# UPD70F3508 register map
Vendor: Renesas; Series: V850E2/Px4; File version: 1.0
CPU: other r0p0, little endian, no MPU, FPU, 4 interrupt priority bits
Registers are 8-bit, read-write, reset 0x0 unless marked. A register's access mark holds for its fields unless they carry their own. Offsets are from the block's base; [hi:lo] are bit positions.

## CSIG0_B0 — Clocked Serial Interface G 0 - base0 region (CTL1, CTL2, CFG0)
Base 0xFF700010
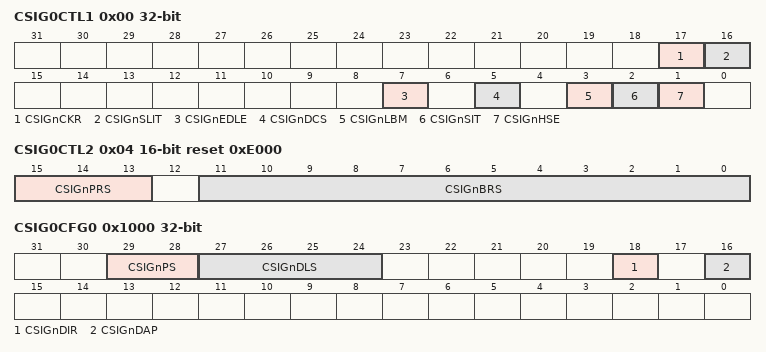
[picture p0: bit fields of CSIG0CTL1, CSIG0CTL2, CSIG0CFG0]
0x00 CSIG0CTL1 32-bit — CSIG0 Control Register 1
  [17] CSIGnCKR — Clock phase selection: 0=SCK default high, 1=SCK default low
  [16] CSIGnSLIT — TIC interrupt timing: 0=after transfer, 1=when TX0W/H free
  [7] CSIGnEDLE — Extended data length enable: 0=disabled, 1=enabled
  [5] CSIGnDCS — Data consistency check enable: 0=disabled, 1=enabled
  [3] CSIGnLBM — Loop-back mode: 0=deactivated, 1=activated
  [2] CSIGnSIT — Interrupt delay: 0=no delay, 1=half-clock delay
  [1] CSIGnHSE — Handshake enable: 0=disabled, 1=enabled
0x04 CSIG0CTL2 16-bit reset 0xE000 — CSIG0 Control Register 2 - baud rate generator
  [15:13] CSIGnPRS — Prescaler select [2:0]: 000-110=PCLK/2^m master, 111=slave ext clock
  [11:0] CSIGnBRS — Baud rate select [11:0]: 0=BRG stopped, 1-4095=divisor k
0x1000 CSIG0CFG0 32-bit — CSIG0 Configuration Register 0 - protocol, data length, parity, direction, clock/data phase
  [29:28] CSIGnPS — Parity select [1:0]: 00=none, 01=fixed-0, 10=odd, 11=even
  [27:24] CSIGnDLS — Data length select [3:0]: 0=16-bit, 1-15=N bits
  [18] CSIGnDIR — Transfer direction: 0=MSB first, 1=LSB first
  [16] CSIGnDAP — Data phase selection (used with CKR for SPI mode)

## CSIG1_B0 — Clocked Serial Interface G 1 - base0 region (CTL1, CTL2, CFG0)
Base 0xFF710010
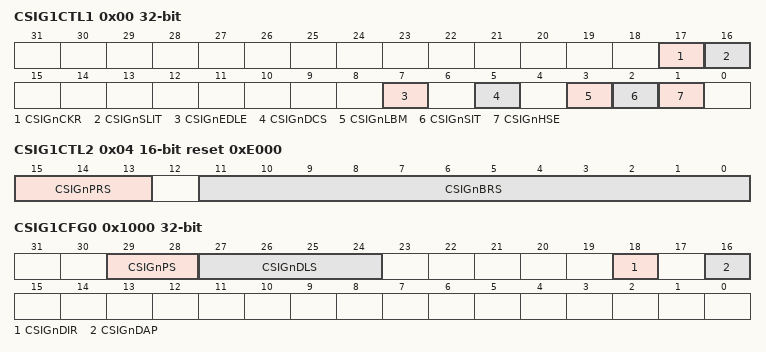
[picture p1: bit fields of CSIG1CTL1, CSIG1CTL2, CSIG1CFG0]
0x00 CSIG1CTL1 32-bit — CSIG1 Control Register 1
  [17] CSIGnCKR — Clock phase selection: 0=SCK default high, 1=SCK default low
  [16] CSIGnSLIT — TIC interrupt timing: 0=after transfer, 1=when TX0W/H free
  [7] CSIGnEDLE — Extended data length enable: 0=disabled, 1=enabled
  [5] CSIGnDCS — Data consistency check enable: 0=disabled, 1=enabled
  [3] CSIGnLBM — Loop-back mode: 0=deactivated, 1=activated
  [2] CSIGnSIT — Interrupt delay: 0=no delay, 1=half-clock delay
  [1] CSIGnHSE — Handshake enable: 0=disabled, 1=enabled
0x04 CSIG1CTL2 16-bit reset 0xE000 — CSIG1 Control Register 2 - baud rate generator
  [15:13] CSIGnPRS — Prescaler select [2:0]: 000-110=PCLK/2^m master, 111=slave ext clock
  [11:0] CSIGnBRS — Baud rate select [11:0]: 0=BRG stopped, 1-4095=divisor k
0x1000 CSIG1CFG0 32-bit — CSIG1 Configuration Register 0 - protocol, data length, parity, direction, clock/data phase
  [29:28] CSIGnPS — Parity select [1:0]: 00=none, 01=fixed-0, 10=odd, 11=even
  [27:24] CSIGnDLS — Data length select [3:0]: 0=16-bit, 1-15=N bits
  [18] CSIGnDIR — Transfer direction: 0=MSB first, 1=LSB first
  [16] CSIGnDAP — Data phase selection (used with CKR for SPI mode)

## CSIG2_B0 — Clocked Serial Interface G 2 - base0 region (CTL1, CTL2, CFG0)
Base 0xFF720010
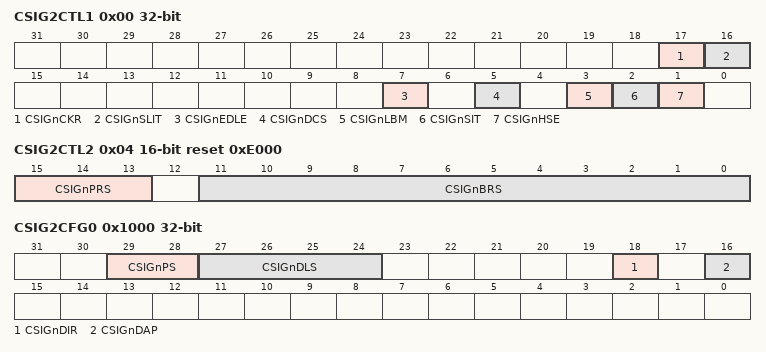
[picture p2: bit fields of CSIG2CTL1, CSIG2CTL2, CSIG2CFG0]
0x00 CSIG2CTL1 32-bit — CSIG2 Control Register 1
  [17] CSIGnCKR — Clock phase selection: 0=SCK default high, 1=SCK default low
  [16] CSIGnSLIT — TIC interrupt timing: 0=after transfer, 1=when TX0W/H free
  [7] CSIGnEDLE — Extended data length enable: 0=disabled, 1=enabled
  [5] CSIGnDCS — Data consistency check enable: 0=disabled, 1=enabled
  [3] CSIGnLBM — Loop-back mode: 0=deactivated, 1=activated
  [2] CSIGnSIT — Interrupt delay: 0=no delay, 1=half-clock delay
  [1] CSIGnHSE — Handshake enable: 0=disabled, 1=enabled
0x04 CSIG2CTL2 16-bit reset 0xE000 — CSIG2 Control Register 2 - baud rate generator
  [15:13] CSIGnPRS — Prescaler select [2:0]: 000-110=PCLK/2^m master, 111=slave ext clock
  [11:0] CSIGnBRS — Baud rate select [11:0]: 0=BRG stopped, 1-4095=divisor k
0x1000 CSIG2CFG0 32-bit — CSIG2 Configuration Register 0 - protocol, data length, parity, direction, clock/data phase
  [29:28] CSIGnPS — Parity select [1:0]: 00=none, 01=fixed-0, 10=odd, 11=even
  [27:24] CSIGnDLS — Data length select [3:0]: 0=16-bit, 1-15=N bits
  [18] CSIGnDIR — Transfer direction: 0=MSB first, 1=LSB first
  [16] CSIGnDAP — Data phase selection (used with CKR for SPI mode)
